# V3s register map
Vendor: Allwinner; Series: V3s; File version: 0.1
CPU: ARM Cortex-A7 MP1 0, little endian, MPU, no FPU, 0 interrupt priority bits
Registers are 32-bit, read-write, reset 0x0 unless marked. A register's access mark holds for its fields unless they carry their own. Offsets are from the block's base; lines under a group give offsets from that group; [hi:lo] are bit positions; {n}, {i} and the like mark numbered series; 'fields as' and 'values as' point back to an identical list; <NAME> marks a mode.

## Memory map
0x01C00000 System_Control
0x01C02000 DMA
0x01C0C000 TCON
0x01C0F000 SD/MMC0
0x01C10000 SD/MMC1
0x01C11000 SD/MMC2
0x01C15000 CE
0x01C1A000 USB_OTG_EHCI0/OHCI0
0x01C20000 CCU
0x01C20400 RTC
0x01C20800 PIO
0x01C20C00 TIMER
0x01C21400 PWM
0x01C22800 LRADC
0x01C22C00 AC
0x01C28000 UART0
0x01C28400 UART1
0x01C28800 UART2
0x01C2AC00 TWI0
0x01C2B000 TWI1
0x01C30000 EMAC
0x01C60000 High_Speed_Timer
0x01C68000 SPI0
0x01CB0000 CSI0
0x01CB4000 CSI1

## System_Control
Base 0x01C00000
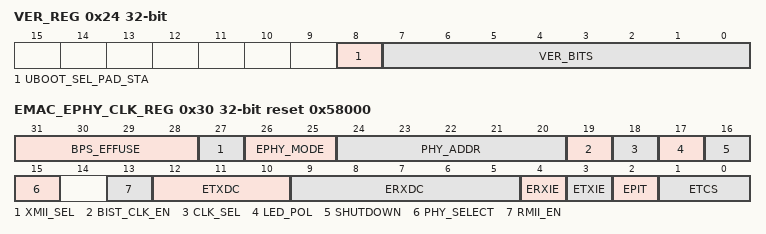
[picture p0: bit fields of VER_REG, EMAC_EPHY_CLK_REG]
0x24 VER_REG (reset mask 0xFF) — Version Register
  [8] UBOOT_SEL_PAD_STA ro — U_boot Select Pin Status. 0: U_Boot; 1: Normal Boot.
    0=U_Boot; 1=Normal Boot
  [7:0] VER_BITS ro — This read-only bit field always reads back the mask revision level of the chip.
0x30 EMAC_EPHY_CLK_REG reset 0x58000
  [31:28] BPS_EFFUSE
  [27] XMII_SEL — 0: Internal SMI and MII 1: External SMI and MII
    0=Internal SMI and MII; 1=External SMI and MII
  [26:25] EPHY_MODE — Operation Mode Selection 00 : Normal Mode 01 : Sim Mode 10 : AFE Test Mode 11 : /
  [24:20] PHY_ADDR — PHY Address
  [19] BIST_CLK_EN — 0 : BIST clk disable 1 : BIST clk enable
  [18] CLK_SEL — 0 : 25MHz 1 : 24MHz
  [17] LED_POL — 0 : High active 1 : Low active
  [16] SHUTDOWN — 0 : Power up 1 : Shutdown
  [15] PHY_SELECT — 0 : External PHY 1 : Internal PHY
  [13] RMII_EN — 0 : Disable RMII Module 1 : Enable RMII Module When this bit assert, MII or RGMII interface is disabled( This means bit13 is prior to bit2)
  [12:10] ETXDC — Configure EMAC Transmit Clock Delay Chain.
  [9:5] ERXDC — Configure EMAC Receive Clock Delay Chain.
  [4] ERXIE — Enable EMAC Receive Clock Invertor. 0: Disable 1: Enable
    0=Disable; 1=Enable
  [3] ETXIE — Enable EMAC Transmit Clock Invertor. 0: Disable 1: Enable
    0=Disable; 1=Enable
  [2] EPIT — EMAC PHY Interface Type 0: MII 1: RGMII
    0=MII; 1=RGMII
  [1:0] ETCS — EMAC Transmit Clock Source 00: Transmit clock source for MII 01: External transmit clock source for GMII and RGMII 10: Internal transmit clock source for GMII and RGMII 11: Reserved
    0=Transmit clock source for MII; 1=External transmit clock source for GMII and RGMII; 2=Internal transmit clock source for GMII and RGMII

## Licence text in the file
questionable
